AUTOSAR XML (schema 314)
package /ComponentType
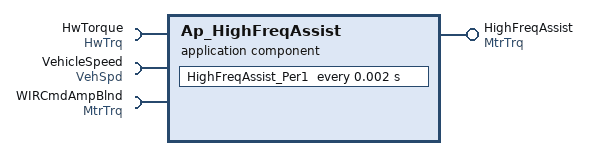
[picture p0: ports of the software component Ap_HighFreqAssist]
  application software component type Ap_HighFreqAssist
    provide port HighFreqAssist: unqueued-sender-com-spec{data-element=MtrNm_f32, can-invalidate=false, init-value=D_ZERO_ULS_F32}, provided-interface=MtrTrq
    require port HwTorque: unqueued-receiver-com-spec{data-element=HwNm_f32, init-value=D_ZERO_ULS_F32}, required-interface=HwTrq
    require port VehicleSpeed: unqueued-receiver-com-spec{data-element=Kph_f32, init-value=D_ZERO_ULS_F32}, required-interface=VehSpd
    require port WIRCmdAmpBlnd: unqueued-receiver-com-spec{data-element=MtrNm_f32, init-value=D_ZERO_ULS_F32}, required-interface=MtrTrq
  internal behavior Ap_HighFreqAssist_InternalBehavior: component=Ap_HighFreqAssist
    timing event TMT_HighFreqAssist_Per1: start-on-event=HighFreqAssist_Per1, period=0.002
    port-api-options:
      enable-take-address=false, indirect-api=false, port=HighFreqAssist
      enable-take-address=false, indirect-api=false, port=HwTorque
      enable-take-address=false, indirect-api=false, port=VehicleSpeed
      enable-take-address=false, indirect-api=false, port=WIRCmdAmpBlnd
    runnable HighFreqAssist_Per1
      data read access READ_HwTorque_HwNm_f32: data-element=HwTorque.HwNm_f32
      data read access READ_VehicleSpeed_Kph_f32: data-element=VehicleSpeed.Kph_f32
      data read access READ_WIRCmdAmpBlnd_MtrNm_f32: data-element=WIRCmdAmpBlnd.MtrNm_f32
      data write access WRITE_HighFreqAssist_MtrNm_f32: data-element=HighFreqAssist.MtrNm_f32
  swc implementation Ap_HighFreqAssist_Implementation: behavior=Ap_HighFreqAssist_InternalBehavior
    code-descriptors:
      code Code: type=SRC
